# ATSAMG55G19 register map
Vendor: Atmel; Series: SAMG55; File version: 0
CPU: CM4 r0p1, selectable endian, MPU, FPU, 4 interrupt priority bits
Registers are 32-bit, read-write, reset 0x0 unless marked. A register's access mark holds for its fields unless they carry their own. Offsets are from the block's base; [hi:lo] are bit positions.

## TWI5 — Two-wire Interface 5
Base 0x40008600; register names take the prefix TWI5_
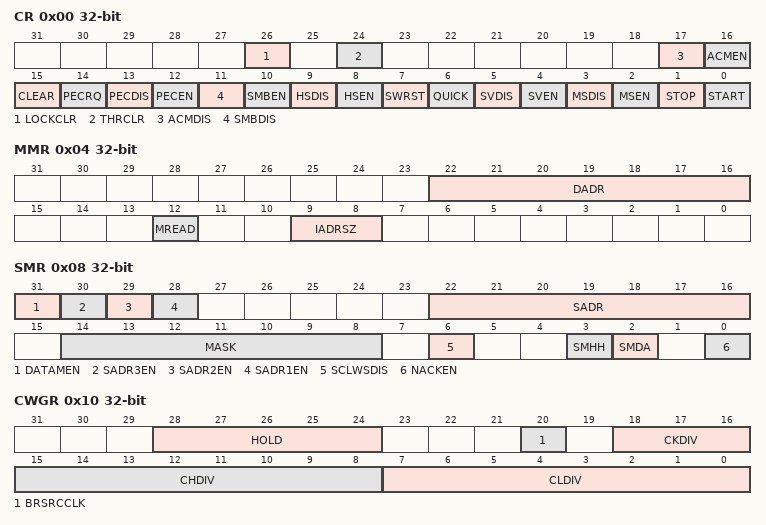
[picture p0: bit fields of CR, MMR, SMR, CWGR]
0x00 CR wo reset not defined — TWI Control Register
  [26] LOCKCLR — Lock Clear
  [24] THRCLR — Transmit Holding Register Clear
  [17] ACMDIS — Alternative Command Mode Disable
  [16] ACMEN — Alternative Command Mode Enable
  [15] CLEAR — Bus CLEAR Command
  [14] PECRQ — PEC Request
  [13] PECDIS — Packet Error Checking Disable
  [12] PECEN — Packet Error Checking Enable
  [11] SMBDIS — SMBus Mode Disabled
  [10] SMBEN — SMBus Mode Enabled
  [9] HSDIS — TWI High-Speed Mode Disabled
  [8] HSEN — TWI High-Speed Mode Enabled
  [7] SWRST — Software Reset
  [6] QUICK — SMBUS Quick Command
  [5] SVDIS — TWI Slave Mode Disabled
  [4] SVEN — TWI Slave Mode Enabled
  [3] MSDIS — TWI Master Mode Disabled
  [2] MSEN — TWI Master Mode Enabled
  [1] STOP — Send a STOP Condition
  [0] START — Send a START Condition
0x04 MMR — TWI Master Mode Register
  [22:16] DADR — Device Address
  [12] MREAD — Master Read Direction
  [9:8] IADRSZ — Internal Device Address Size
    0=NONE (No internal device address); 1=1_BYTE (One-byte internal device address); 2=2_BYTE (Two-byte internal device address); 3=3_BYTE (Three-byte internal device address)
0x08 SMR — TWI Slave Mode Register
  [31] DATAMEN — Data Matching Enable
  [30] SADR3EN — Slave Address 3 Enable
  [29] SADR2EN — Slave Address 2 Enable
  [28] SADR1EN — Slave Address 1 Enable
  [22:16] SADR — Slave Address
  [14:8] MASK — Slave Address Mask
  [6] SCLWSDIS — Clock Wait State Disable
  [3] SMHH — SMBus Host Header
  [2] SMDA — SMBus Default Address
  [0] NACKEN — Slave Receiver Data Phase NACK Enable
0x0C IADR — TWI Internal Address Register
  [23:0] IADR — Internal Address
0x10 CWGR — TWI Clock Waveform Generator Register
  [28:24] HOLD — TWD Hold Time Versus TWCK Falling
  [20] BRSRCCLK — Bit Rate Source Clock
  [18:16] CKDIV — Clock Divider
  [15:8] CHDIV — Clock High Divider
  [7:0] CLDIV — Clock Low Divider
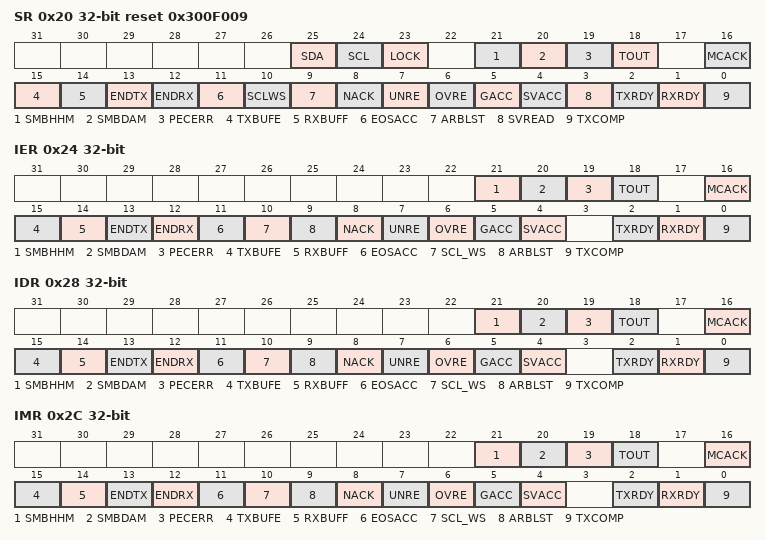
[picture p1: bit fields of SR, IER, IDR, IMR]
0x20 SR ro reset 0x300F009 — TWI Status Register
  [25] SDA — SDA line value
  [24] SCL — SCL line value
  [23] LOCK — TWI Lock due to Frame Errors
  [21] SMBHHM — SMBus Host Header Address Match (cleared on read)
  [20] SMBDAM — SMBus Default Address Match (cleared on read)
  [19] PECERR — PEC Error (cleared on read)
  [18] TOUT — Timeout Error (cleared on read)
  [16] MCACK — Master Code Acknowledge (cleared on read)
  [15] TXBUFE — TX Buffer Empty (cleared by writing TWI_TCR or TWI_TNCR)
  [14] RXBUFF — RX Buffer Full (cleared by writing TWI_RCR or TWI_RNCR)
  [13] ENDTX — End of TX Buffer (cleared by writing TWI_TCR or TWI_TNCR)
  [12] ENDRX — End of RX Buffer (cleared by writing TWI_RCR or TWI_RNCR)
  [11] EOSACC — End Of Slave Access (cleared on read)
  [10] SCLWS — Clock Wait State
  [9] ARBLST — Arbitration Lost (cleared on read)
  [8] NACK — Not Acknowledged (cleared on read)
  [7] UNRE — Underrun Error (cleared on read)
  [6] OVRE — Overrun Error (cleared on read)
  [5] GACC — General Call Access (cleared on read)
  [4] SVACC — Slave Access
  [3] SVREAD — Slave Read
  [2] TXRDY — Transmit Holding Register Ready (cleared by writing TWI_THR)
  [1] RXRDY — Receive Holding Register Ready (cleared when reading TWI_RHR)
  [0] TXCOMP — Transmission Completed (cleared by writing TWI_THR)
0x24 IER wo reset not defined — TWI Interrupt Enable Register
  [21] SMBHHM — SMBus Host Header Address Match Interrupt Enable
  [20] SMBDAM — SMBus Default Address Match Interrupt Enable
  [19] PECERR — PEC Error Interrupt Enable
  [18] TOUT — Timeout Error Interrupt Enable
  [16] MCACK — Master Code Acknowledge Interrupt Enable
  [15] TXBUFE — Transmit Buffer Empty Interrupt Enable
  [14] RXBUFF — Receive Buffer Full Interrupt Enable
  [13] ENDTX — End of Transmit Buffer Interrupt Enable
  [12] ENDRX — End of Receive Buffer Interrupt Enable
  [11] EOSACC — End Of Slave Access Interrupt Enable
  [10] SCL_WS — Clock Wait State Interrupt Enable
  [9] ARBLST — Arbitration Lost Interrupt Enable
  [8] NACK — Not Acknowledge Interrupt Enable
  [7] UNRE — Underrun Error Interrupt Enable
  [6] OVRE — Overrun Error Interrupt Enable
  [5] GACC — General Call Access Interrupt Enable
  [4] SVACC — Slave Access Interrupt Enable
  [2] TXRDY — Transmit Holding Register Ready Interrupt Enable
  [1] RXRDY — Receive Holding Register Ready Interrupt Enable
  [0] TXCOMP — Transmission Completed Interrupt Enable
0x28 IDR wo reset not defined — TWI Interrupt Disable Register
  [21] SMBHHM — SMBus Host Header Address Match Interrupt Disable
  [20] SMBDAM — SMBus Default Address Match Interrupt Disable
  [19] PECERR — PEC Error Interrupt Disable
  [18] TOUT — Timeout Error Interrupt Disable
  [16] MCACK — Master Code Acknowledge Interrupt Disable
  [15] TXBUFE — Transmit Buffer Empty Interrupt Disable
  [14] RXBUFF — Receive Buffer Full Interrupt Disable
  [13] ENDTX — End of Transmit Buffer Interrupt Disable
  [12] ENDRX — End of Receive Buffer Interrupt Disable
  [11] EOSACC — End Of Slave Access Interrupt Disable
  [10] SCL_WS — Clock Wait State Interrupt Disable
  [9] ARBLST — Arbitration Lost Interrupt Disable
  [8] NACK — Not Acknowledge Interrupt Disable
  [7] UNRE — Underrun Error Interrupt Disable
  [6] OVRE — Overrun Error Interrupt Disable
  [5] GACC — General Call Access Interrupt Disable
  [4] SVACC — Slave Access Interrupt Disable
  [2] TXRDY — Transmit Holding Register Ready Interrupt Disable
  [1] RXRDY — Receive Holding Register Ready Interrupt Disable
  [0] TXCOMP — Transmission Completed Interrupt Disable
0x2C IMR ro — TWI Interrupt Mask Register
  [21] SMBHHM — SMBus Host Header Address Match Interrupt Mask
  [20] SMBDAM — SMBus Default Address Match Interrupt Mask
  [19] PECERR — PEC Error Interrupt Mask
  [18] TOUT — Timeout Error Interrupt Mask
  [16] MCACK — Master Code Acknowledge Interrupt Mask
  [15] TXBUFE — Transmit Buffer Empty Interrupt Mask
  [14] RXBUFF — Receive Buffer Full Interrupt Mask
  [13] ENDTX — End of Transmit Buffer Interrupt Mask
  [12] ENDRX — End of Receive Buffer Interrupt Mask
  [11] EOSACC — End Of Slave Access Interrupt Mask
  [10] SCL_WS — Clock Wait State Interrupt Mask
  [9] ARBLST — Arbitration Lost Interrupt Mask
  [8] NACK — Not Acknowledge Interrupt Mask
  [7] UNRE — Underrun Error Interrupt Mask
  [6] OVRE — Overrun Error Interrupt Mask
  [5] GACC — General Call Access Interrupt Mask
  [4] SVACC — Slave Access Interrupt Mask
  [2] TXRDY — Transmit Holding Register Ready Interrupt Mask
  [1] RXRDY — Receive Holding Register Ready Interrupt Mask
  [0] TXCOMP — Transmission Completed Interrupt Mask
0x30 RHR ro — TWI Receive Holding Register
  [7:0] RXDATA — Master or Slave Receive Holding Data
0x34 THR wo — TWI Transmit Holding Register
  [7:0] TXDATA — Master or Slave Transmit Holding Data
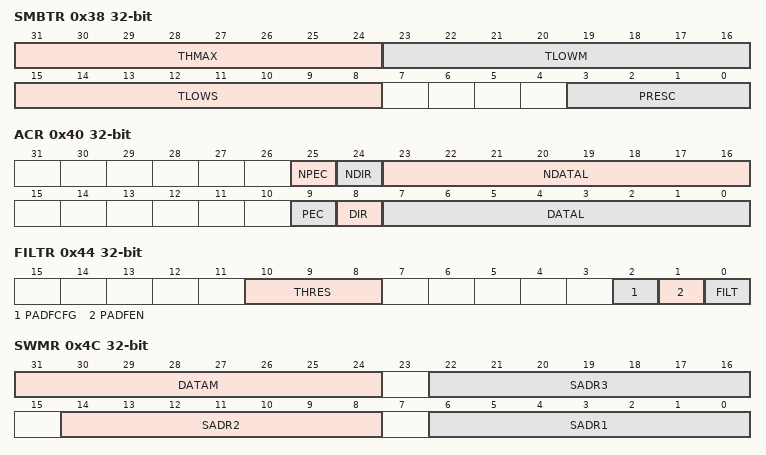
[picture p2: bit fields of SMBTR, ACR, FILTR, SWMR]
0x38 SMBTR — TWI SMBus Timing Register
  [31:24] THMAX — Clock High Maximum Cycles
  [23:16] TLOWM — Master Clock Stretch Maximum Cycles
  [15:8] TLOWS — Slave Clock Stretch Maximum Cycles
  [3:0] PRESC — SMBus Clock Prescaler
0x40 ACR reset not defined — TWI Alternative Command Register
  [25] NPEC — Next PEC Request (SMBus Mode only)
  [24] NDIR — Next Transfer Direction
  [23:16] NDATAL — Next Data Length
  [9] PEC — PEC Request (SMBus Mode only)
  [8] DIR — Transfer Direction
  [7:0] DATAL — Data Length
0x44 FILTR — TWI Filter Register
  [10:8] THRES — Digital Filter Threshold
  [2] PADFCFG — PAD Filter Config
  [1] PADFEN — PAD Filter Enable
  [0] FILT — RX Digital Filter
0x4C SWMR — TWI SleepWalking Matching Register
  [31:24] DATAM — Data Match
  [22:16] SADR3 — Slave Address 3
  [14:8] SADR2 — Slave Address 2
  [6:0] SADR1 — Slave Address 1
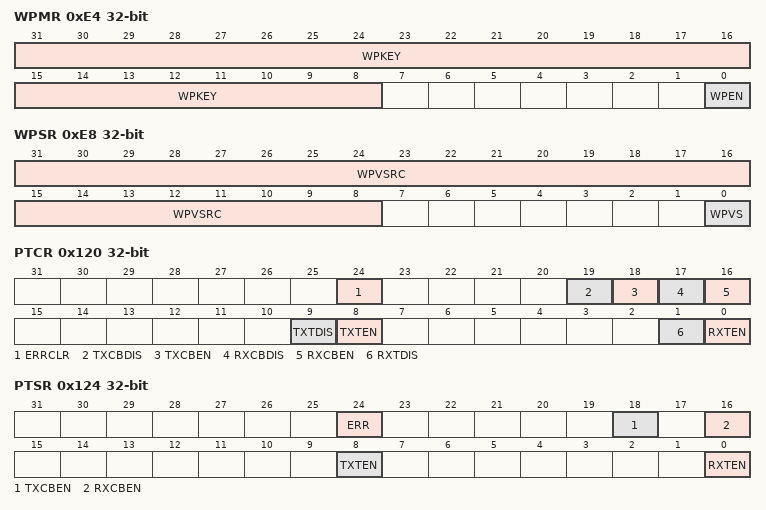
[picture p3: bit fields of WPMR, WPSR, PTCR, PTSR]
0xE4 WPMR — TWI Write Protection Mode Register
  [31:8] WPKEY — Write Protection Key
    0x545749=PASSWD (Writing any other value in this field aborts the write operation of the WPEN bit.Always reads as 0)
  [0] WPEN — Write Protection Enable
0xE8 WPSR ro — TWI Write Protection Status Register
  [31:8] WPVSRC — Write Protection Violation Source
  [0] WPVS — Write Protect Violation Status
0x100 RPR — Receive Pointer Register
  [31:0] RXPTR
0x104 RCR — Receive Counter Register
  [15:0] RXCTR
0x108 TPR — Transmit Pointer Register
  [31:0] TXPTR — Transmit Counter Register
0x10C TCR — Transmit Counter Register
  [15:0] TXCTR
0x110 RNPR — Receive Next Pointer Register
  [31:0] RXNPTR — Receive Next Pointer
0x114 RNCR — Receive Next Counter Register
  [15:0] RXNCTR — Receive Next Counter
0x118 TNPR — Transmit Next Pointer Register
  [31:0] TXNPTR — Transmit Next Pointer
0x11C TNCR — Transmit Next Counter Register
  [15:0] TXNCTR — Transmit Counter Next
0x120 PTCR wo reset not defined — Transfer Control Register
  [24] ERRCLR — Transfer Bus Error Clear
  [19] TXCBDIS — Transmitter Circular Buffer Disable
  [18] TXCBEN — Transmitter Circular Buffer Enable
  [17] RXCBDIS — Receiver Circular Buffer Disable
  [16] RXCBEN — Receiver Circular Buffer Enable
  [9] TXTDIS — Transmitter Transfer Disable
  [8] TXTEN — Transmitter Transfer Enable
  [1] RXTDIS — Receiver Transfer Disable
  [0] RXTEN — Receiver Transfer Enable
0x124 PTSR ro — Transfer Status Register
  [24] ERR — Transfer Bus Error
  [18] TXCBEN — Transmitter Circular Buffer Enable
  [16] RXCBEN — Receiver Circular Buffer Enable
  [8] TXTEN — Transmitter Transfer Enable
  [0] RXTEN — Receiver Transfer Enable

## TWI0 — Two-wire Interface 0
Base 0x4000C600; register names take the prefix TWI0_
Registers as TWI5.

## TWI3 — Two-wire Interface 3
Base 0x40018600; register names take the prefix TWI3_
Registers as TWI5.

## TWI4 — Two-wire Interface 4
Base 0x4001C600; register names take the prefix TWI4_
Registers as TWI5.

## TWI1 — Two-wire Interface 1
Base 0x40020600; register names take the prefix TWI1_
Registers as TWI5.

## TWI2 — Two-wire Interface 2
Base 0x40024600; register names take the prefix TWI2_
Registers as TWI5.

## TWI6 — Two-wire Interface 6
Base 0x40040600; register names take the prefix TWI6_
Registers as TWI5.
